# tmpm373 register map
File version: 0.1
CPU: CM3 r2p0, little endian, no MPU, no FPU, 4 interrupt priority bits
Registers are 32-bit, read-write, reset 0x0 unless marked. A register's access mark holds for its fields unless they carry their own. Offsets are from the block's base; [hi:lo] are bit positions; {n}, {i} and the like mark numbered series.

## WD — Watchdog Timer (WD)
Base 0x40040000
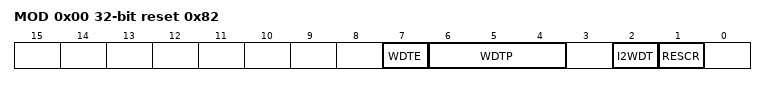
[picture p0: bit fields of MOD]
0x00 MOD reset 0x82 — WD Mode Register
  [7] WDTE, [6:4] WDTP, [2] I2WDT, [1] RESCR
0x04 CR wo (reset mask 0xFFFFFF00) — WD Control Register

## CG — Clock Generator (CG)
Base 0x40040200
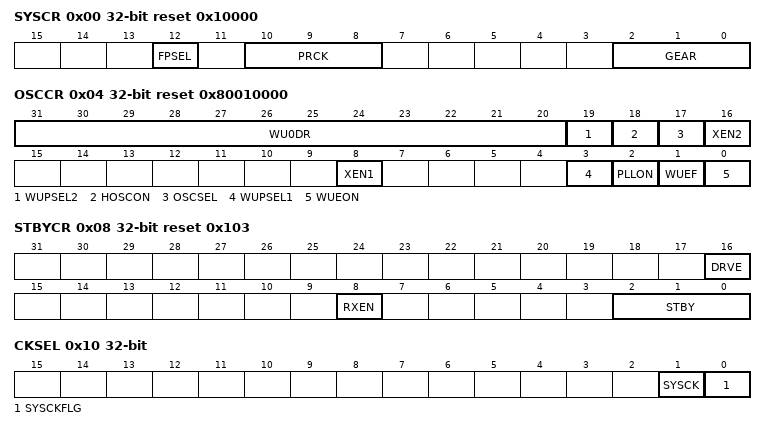
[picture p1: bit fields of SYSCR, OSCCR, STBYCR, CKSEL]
0x00 SYSCR reset 0x10000 — System Control Register
  [12] FPSEL, [10:8] PRCK, [2:0] GEAR
0x04 OSCCR reset 0x80010000 — Oscillation Control Register
  [31:20] WU0DR, [19] WUPSEL2, [18] HOSCON, [17] OSCSEL, [16] XEN2, [8] XEN1, [3] WUPSEL1, [2] PLLON, [1] WUEF ro, [0] WUEON wo
0x08 STBYCR reset 0x103 — Standby Control Register
  [16] DRVE, [8] RXEN, [2:0] STBY
0x0C PLLSEL reset 0xA13E — PLL Selection Register
  [0] PLLSEL
0x10 CKSEL — System Clock Selection Register
  [1] SYSCK, [0] SYSCKFLG ro
0x14 ICRCG wo — CG Interrupt Request Clear Register
  [4:0] ICRCG
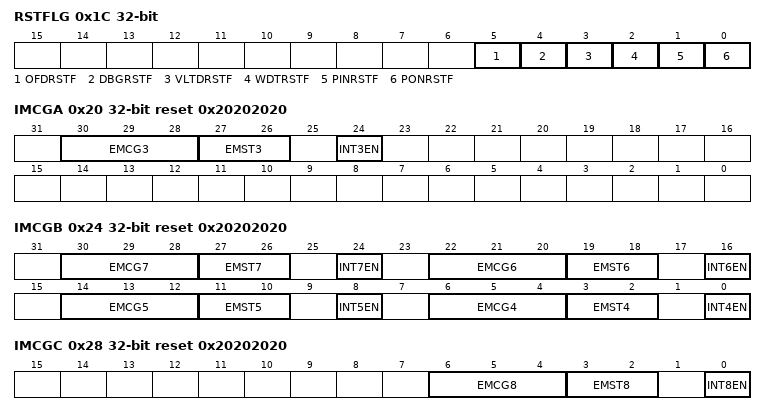
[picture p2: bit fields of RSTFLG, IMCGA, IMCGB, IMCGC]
0x1C RSTFLG (reset mask 0xFFFFFFFE) — Reset Flag Register
  [5] OFDRSTF, [4] DBGRSTF, [3] VLTDRSTF, [2] WDTRSTF, [1] PINRSTF, [0] PONRSTF
0x20 IMCGA reset 0x20202020 — CG Interrupt Mode Control Register A
  [30:28] EMCG3, [27:26] EMST3 ro, [24] INT3EN
0x24 IMCGB reset 0x20202020 — CG Interrupt Mode Control Register B
  [8n-26:8n-28] EMCG{n} (n=4..7), [8n-29:8n-30] EMST{n} ro (n=4..7), [8n-32] INT{n}EN (n=4..7)
0x28 IMCGC reset 0x20202020 — CG Interrupt Mode Control Register C
  [6:4] EMCG8, [3:2] EMST8 ro, [0] INT8EN
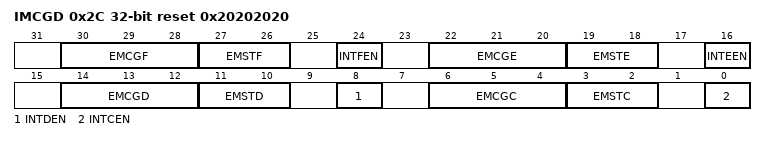
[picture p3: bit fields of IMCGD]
0x2C IMCGD reset 0x20202020 — CG Interrupt Mode Control Register D
  [30:28] EMCGF, [27:26] EMSTF ro, [24] INTFEN, [22:20] EMCGE, [19:18] EMSTE ro, [16] INTEEN, [14:12] EMCGD, [11:10] EMSTD ro, [8] INTDEN, [6:4] EMCGC, [3:2] EMSTC ro, [0] INTCEN

## OFD — Oscillation Frequency Detector (OFD)
Base 0x40040800
0x00 CR1 reset 0x6 — OFD Control Register 1
  [7:0] OFDWEN
0x04 CR2 — OFD Control Register 2
  [7:0] OFDEN
0x08 MNPLLOFF reset 0x1A — OFD Lower Detection Frequency Setting Register
  [8:0] OFDMNPLLOFF
0x0C MNPLLON reset 0xD1 — OFD Lower Detection Frequency Setting Register
  [8:0] OFDMNPLLON
0x10 MXPLLOFF reset 0x28 — OFD Higher Detection Frequency Setting Register
  [8:0] OFDMXPLLOFF
0x14 MXPLLON reset 0x139 — OFD Higher Detection Frequency Setting Register
  [8:0] OFDMXPLLON

## VD — Power-On Reset Circuit (POR)
Base 0x40040900
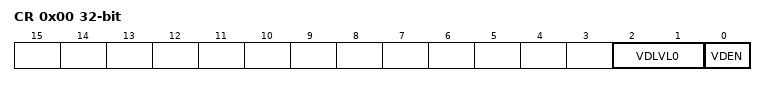
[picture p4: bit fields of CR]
0x00 CR — VD Control Register
  [2:1] VDLVL0, [0] VDEN

## PMD — 16-bit Multi-Purpose Timer (MPT-PMD)
Base 0x40050480
0x00 MDEN — PMD Enable Register
  [0] PWMEN
0x04 PORTMD — Port Output Mode Register
  [1:0] PORTMD
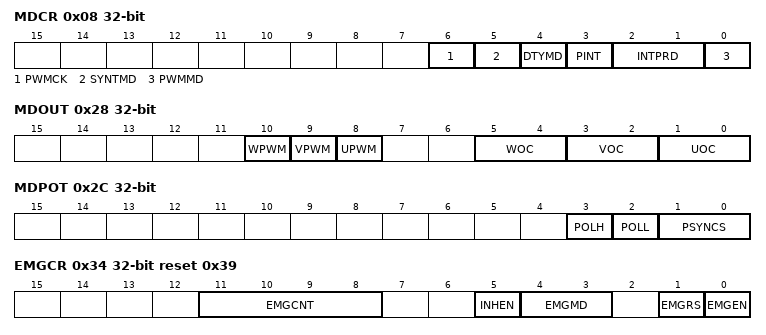
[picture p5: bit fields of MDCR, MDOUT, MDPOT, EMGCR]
0x08 MDCR — PMD Control Register
  [6] PWMCK, [5] SYNTMD, [4] DTYMD, [3] PINT, [2:1] INTPRD, [0] PWMMD
0x0C CNTSTA ro — PWM Counter Status Register
  [0] UPDWN
0x10 MDCNT ro reset 0x1 — PWM Counter Register
  [15:0] MDCNT
0x14 MDPRD — PWM Period Register
  [15:0] MDPRD
0x18 CMPU — PWM Compare Register
  [15:0] CMPU1
0x1C CMPV — PWM Compare Register
  [15:0] CMPV1
0x20 CMPW — PWM Compare Register
  [15:0] CMPW1
0x24 MODESEL — PWM Mode Select Register
  [0] MDSEL
0x28 MDOUT — PMD Output Control Register
  [10] WPWM, [9] VPWM, [8] UPWM, [5:4] WOC, [3:2] VOC, [1:0] UOC
0x2C MDPOT — PMD Output Setting Register
  [3] POLH, [2] POLL, [1:0] PSYNCS
0x30 EMGREL wo — EMG Release Register
  [7:0] EMGREL
0x34 EMGCR reset 0x39 — EMG Control Register
  [11:8] EMGCNT, [5] INHEN wo, [4:3] EMGMD, [1] EMGRS wo, [0] EMGEN
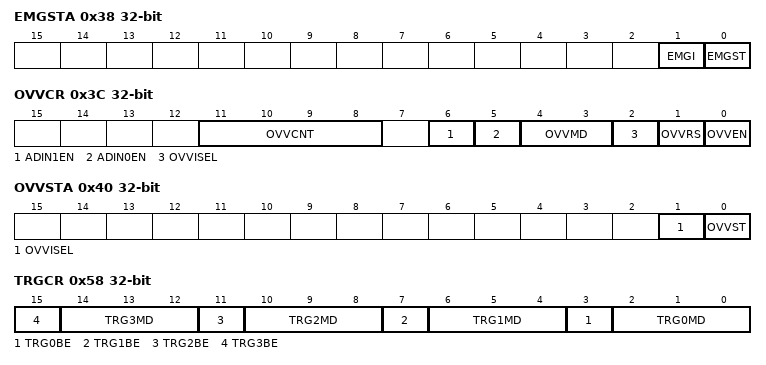
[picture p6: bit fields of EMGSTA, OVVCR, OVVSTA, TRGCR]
0x38 EMGSTA ro (reset mask 0xFFFFFFFD) — EMG Status Register
  [1] EMGI, [0] EMGST
0x3C OVVCR — OVV Control Register
  [11:8] OVVCNT, [6] ADIN1EN, [5] ADIN0EN, [4:3] OVVMD, [2] OVVISEL, [1] OVVRS, [0] OVVEN
0x40 OVVSTA ro (reset mask 0xFFFFFFFD) — OVV Status Register
  [1] OVVISEL, [0] OVVST
0x44 DTR — Dead Time Register
  [7:0] DTR
{0x48+4i} TRGCMP{i} (i=0..3) — Trigger Compare Register {i}
  [15:0] TRGCMP{i}
0x58 TRGCR — Trigger Control Register
  [4n+3] TRG{n}BE (n=0..3), [4n+2:4n] TRG{n}MD (n=0..3)
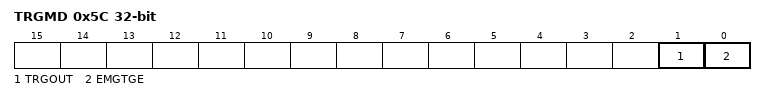
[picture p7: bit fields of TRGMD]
0x5C TRGMD — Trigger Output Mode Setting Register
  [1] TRGOUT, [0] EMGTGE
0x60 TRGSEL — Trigger Output Select Register
  [2:0] TRGSEL

## FC — Flash Control (FC)
Base 0x41FFF010
0x00 SECBIT reset 0x1 — FC Security Bit Register
  [0] SECBIT
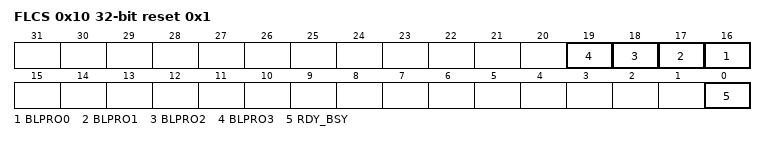
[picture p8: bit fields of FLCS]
0x10 FLCS ro reset 0x1 (reset mask 0xFFF0FFFF) — FC Register
  [n+16] BLPRO{n} (n=0..3), [0] RDY_BSY
